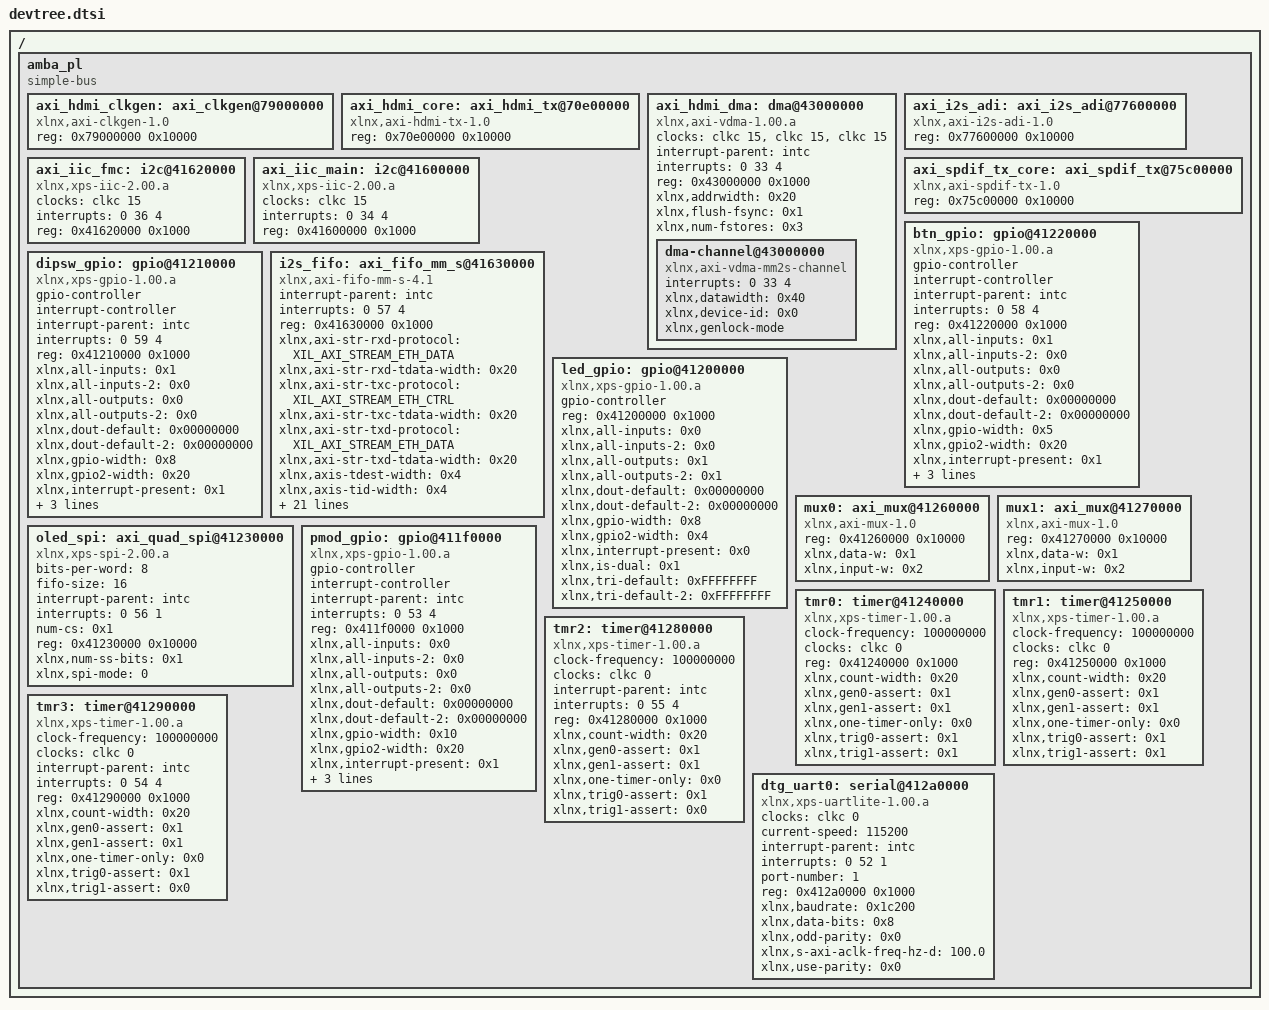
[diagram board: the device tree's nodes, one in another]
/*
 * CAUTION: This file is automatically generated by Xilinx.
 * Version: HSI 2017.1
 * Today is: Wed Jan 24 18:32:57 2018
*/


/ {
	amba_pl: amba_pl {
		#address-cells = <1>;
		#size-cells = <1>;
		compatible = "simple-bus";
		ranges ;
		axi_hdmi_clkgen: axi_clkgen@79000000 {
			compatible = "xlnx,axi-clkgen-1.0";
			reg = <0x79000000 0x10000>;
		};
		axi_hdmi_core: axi_hdmi_tx@70e00000 {
			compatible = "xlnx,axi-hdmi-tx-1.0";
			reg = <0x70e00000 0x10000>;
		};
		axi_hdmi_dma: dma@43000000 {
			#dma-cells = <1>;
			clock-names = "s_axi_lite_aclk", "m_axi_mm2s_aclk", "m_axi_mm2s_aclk";
			clocks = <&clkc 15>, <&clkc 15>, <&clkc 15>;
			compatible = "xlnx,axi-vdma-1.00.a";
			interrupt-parent = <&intc>;
			interrupts = <0 33 4>;
			reg = <0x43000000 0x1000>;
			xlnx,addrwidth = <0x20>;
			xlnx,flush-fsync = <0x1>;
			xlnx,num-fstores = <0x3>;
			dma-channel@43000000 {
				compatible = "xlnx,axi-vdma-mm2s-channel";
				interrupts = <0 33 4>;
				xlnx,datawidth = <0x40>;
				xlnx,device-id = <0x0>;
				xlnx,genlock-mode ;
			};
		};
		axi_i2s_adi: axi_i2s_adi@77600000 {
			compatible = "xlnx,axi-i2s-adi-1.0";
			reg = <0x77600000 0x10000>;
		};
		axi_iic_fmc: i2c@41620000 {
			#address-cells = <1>;
			#size-cells = <0>;
			clock-names = "ref_clk";
			clocks = <&clkc 15>;
			compatible = "xlnx,xps-iic-2.00.a";
			interrupts = <0 36 4>;
			reg = <0x41620000 0x1000>;
		};
		axi_iic_main: i2c@41600000 {
			#address-cells = <1>;
			#size-cells = <0>;
			clock-names = "ref_clk";
			clocks = <&clkc 15>;
			compatible = "xlnx,xps-iic-2.00.a";
			interrupts = <0 34 4>;
			reg = <0x41600000 0x1000>;
		};
		axi_spdif_tx_core: axi_spdif_tx@75c00000 {
			compatible = "xlnx,axi-spdif-tx-1.0";
			reg = <0x75c00000 0x10000>;
		};
		btn_gpio: gpio@41220000 {
			#gpio-cells = <2>;
			#interrupt-cells = <2>;
			compatible = "xlnx,xps-gpio-1.00.a";
			gpio-controller ;
			interrupt-controller ;
			interrupt-parent = <&intc>;
			interrupts = <0 58 4>;
			reg = <0x41220000 0x1000>;
			xlnx,all-inputs = <0x1>;
			xlnx,all-inputs-2 = <0x0>;
			xlnx,all-outputs = <0x0>;
			xlnx,all-outputs-2 = <0x0>;
			xlnx,dout-default = <0x00000000>;
			xlnx,dout-default-2 = <0x00000000>;
			xlnx,gpio-width = <0x5>;
			xlnx,gpio2-width = <0x20>;
			xlnx,interrupt-present = <0x1>;
			xlnx,is-dual = <0x0>;
			xlnx,tri-default = <0xFFFFFFFF>;
			xlnx,tri-default-2 = <0xFFFFFFFF>;
		};
		dipsw_gpio: gpio@41210000 {
			#gpio-cells = <2>;
			#interrupt-cells = <2>;
			compatible = "xlnx,xps-gpio-1.00.a";
			gpio-controller ;
			interrupt-controller ;
			interrupt-parent = <&intc>;
			interrupts = <0 59 4>;
			reg = <0x41210000 0x1000>;
			xlnx,all-inputs = <0x1>;
			xlnx,all-inputs-2 = <0x0>;
			xlnx,all-outputs = <0x0>;
			xlnx,all-outputs-2 = <0x0>;
			xlnx,dout-default = <0x00000000>;
			xlnx,dout-default-2 = <0x00000000>;
			xlnx,gpio-width = <0x8>;
			xlnx,gpio2-width = <0x20>;
			xlnx,interrupt-present = <0x1>;
			xlnx,is-dual = <0x0>;
			xlnx,tri-default = <0xFFFFFFFF>;
			xlnx,tri-default-2 = <0xFFFFFFFF>;
		};
		i2s_fifo: axi_fifo_mm_s@41630000 {
			compatible = "xlnx,axi-fifo-mm-s-4.1";
			interrupt-parent = <&intc>;
			interrupts = <0 57 4>;
			reg = <0x41630000 0x1000>;
			xlnx,axi-str-rxd-protocol = "XIL_AXI_STREAM_ETH_DATA";
			xlnx,axi-str-rxd-tdata-width = <0x20>;
			xlnx,axi-str-txc-protocol = "XIL_AXI_STREAM_ETH_CTRL";
			xlnx,axi-str-txc-tdata-width = <0x20>;
			xlnx,axi-str-txd-protocol = "XIL_AXI_STREAM_ETH_DATA";
			xlnx,axi-str-txd-tdata-width = <0x20>;
			xlnx,axis-tdest-width = <0x4>;
			xlnx,axis-tid-width = <0x4>;
			xlnx,axis-tuser-width = <0x4>;
			xlnx,data-interface-type = <0x0>;
			xlnx,has-axis-tdest = <0x0>;
			xlnx,has-axis-tid = <0x0>;
			xlnx,has-axis-tkeep = <0x0>;
			xlnx,has-axis-tstrb = <0x0>;
			xlnx,has-axis-tuser = <0x0>;
			xlnx,rx-fifo-depth = <0x200>;
			xlnx,rx-fifo-pe-threshold = <0x2>;
			xlnx,rx-fifo-pf-threshold = <0x1fb>;
			xlnx,s-axi-id-width = <0x4>;
			xlnx,s-axi4-data-width = <0x20>;
			xlnx,select-xpm = <0x0>;
			xlnx,tx-fifo-depth = <0x200>;
			xlnx,tx-fifo-pe-threshold = <0x2>;
			xlnx,tx-fifo-pf-threshold = <0x1fb>;
			xlnx,use-rx-cut-through = <0x0>;
			xlnx,use-rx-data = <0x1>;
			xlnx,use-tx-ctrl = <0x0>;
			xlnx,use-tx-cut-through = <0x0>;
			xlnx,use-tx-data = <0x1>;
		};
		led_gpio: gpio@41200000 {
			#gpio-cells = <2>;
			compatible = "xlnx,xps-gpio-1.00.a";
			gpio-controller ;
			reg = <0x41200000 0x1000>;
			xlnx,all-inputs = <0x0>;
			xlnx,all-inputs-2 = <0x0>;
			xlnx,all-outputs = <0x1>;
			xlnx,all-outputs-2 = <0x1>;
			xlnx,dout-default = <0x00000000>;
			xlnx,dout-default-2 = <0x00000000>;
			xlnx,gpio-width = <0x8>;
			xlnx,gpio2-width = <0x4>;
			xlnx,interrupt-present = <0x0>;
			xlnx,is-dual = <0x1>;
			xlnx,tri-default = <0xFFFFFFFF>;
			xlnx,tri-default-2 = <0xFFFFFFFF>;
		};
		mux0: axi_mux@41260000 {
			compatible = "xlnx,axi-mux-1.0";
			reg = <0x41260000 0x10000>;
			xlnx,data-w = <0x1>;
			xlnx,input-w = <0x2>;
		};
		mux1: axi_mux@41270000 {
			compatible = "xlnx,axi-mux-1.0";
			reg = <0x41270000 0x10000>;
			xlnx,data-w = <0x1>;
			xlnx,input-w = <0x2>;
		};
		oled_spi: axi_quad_spi@41230000 {
			bits-per-word = <8>;
			compatible = "xlnx,xps-spi-2.00.a";
			fifo-size = <16>;
			interrupt-parent = <&intc>;
			interrupts = <0 56 1>;
			num-cs = <0x1>;
			reg = <0x41230000 0x10000>;
			xlnx,num-ss-bits = <0x1>;
			xlnx,spi-mode = <0>;
		};
		pmod_gpio: gpio@411f0000 {
			#gpio-cells = <2>;
			#interrupt-cells = <2>;
			compatible = "xlnx,xps-gpio-1.00.a";
			gpio-controller ;
			interrupt-controller ;
			interrupt-parent = <&intc>;
			interrupts = <0 53 4>;
			reg = <0x411f0000 0x1000>;
			xlnx,all-inputs = <0x0>;
			xlnx,all-inputs-2 = <0x0>;
			xlnx,all-outputs = <0x0>;
			xlnx,all-outputs-2 = <0x0>;
			xlnx,dout-default = <0x00000000>;
			xlnx,dout-default-2 = <0x00000000>;
			xlnx,gpio-width = <0x10>;
			xlnx,gpio2-width = <0x20>;
			xlnx,interrupt-present = <0x1>;
			xlnx,is-dual = <0x0>;
			xlnx,tri-default = <0xFFFFFFFF>;
			xlnx,tri-default-2 = <0xFFFFFFFF>;
		};
		tmr0: timer@41240000 {
			clock-frequency = <100000000>;
			clock-names = "ref_clk";
			clocks = <&clkc 0>;
			compatible = "xlnx,xps-timer-1.00.a";
			reg = <0x41240000 0x1000>;
			xlnx,count-width = <0x20>;
			xlnx,gen0-assert = <0x1>;
			xlnx,gen1-assert = <0x1>;
			xlnx,one-timer-only = <0x0>;
			xlnx,trig0-assert = <0x1>;
			xlnx,trig1-assert = <0x1>;
		};
		tmr1: timer@41250000 {
			clock-frequency = <100000000>;
			clock-names = "ref_clk";
			clocks = <&clkc 0>;
			compatible = "xlnx,xps-timer-1.00.a";
			reg = <0x41250000 0x1000>;
			xlnx,count-width = <0x20>;
			xlnx,gen0-assert = <0x1>;
			xlnx,gen1-assert = <0x1>;
			xlnx,one-timer-only = <0x0>;
			xlnx,trig0-assert = <0x1>;
			xlnx,trig1-assert = <0x1>;
		};
		tmr2: timer@41280000 {
			clock-frequency = <100000000>;
			clock-names = "ref_clk";
			clocks = <&clkc 0>;
			compatible = "xlnx,xps-timer-1.00.a";
			interrupt-parent = <&intc>;
			interrupts = <0 55 4>;
			reg = <0x41280000 0x1000>;
			xlnx,count-width = <0x20>;
			xlnx,gen0-assert = <0x1>;
			xlnx,gen1-assert = <0x1>;
			xlnx,one-timer-only = <0x0>;
			xlnx,trig0-assert = <0x1>;
			xlnx,trig1-assert = <0x0>;
		};
		tmr3: timer@41290000 {
			clock-frequency = <100000000>;
			clock-names = "ref_clk";
			clocks = <&clkc 0>;
			compatible = "xlnx,xps-timer-1.00.a";
			interrupt-parent = <&intc>;
			interrupts = <0 54 4>;
			reg = <0x41290000 0x1000>;
			xlnx,count-width = <0x20>;
			xlnx,gen0-assert = <0x1>;
			xlnx,gen1-assert = <0x1>;
			xlnx,one-timer-only = <0x0>;
			xlnx,trig0-assert = <0x1>;
			xlnx,trig1-assert = <0x0>;
		};
		dtg_uart0: serial@412a0000 {
			clock-names = "ref_clk";
			clocks = <&clkc 0>;
			compatible = "xlnx,xps-uartlite-1.00.a";
			current-speed = <115200>;
			device_type = "serial";
			interrupt-parent = <&intc>;
			interrupts = <0 52 1>;
			port-number = <1>;
			reg = <0x412a0000 0x1000>;
			xlnx,baudrate = <0x1c200>;
			xlnx,data-bits = <0x8>;
			xlnx,odd-parity = <0x0>;
			xlnx,s-axi-aclk-freq-hz-d = "100.0";
			xlnx,use-parity = <0x0>;
		};
	};
};
